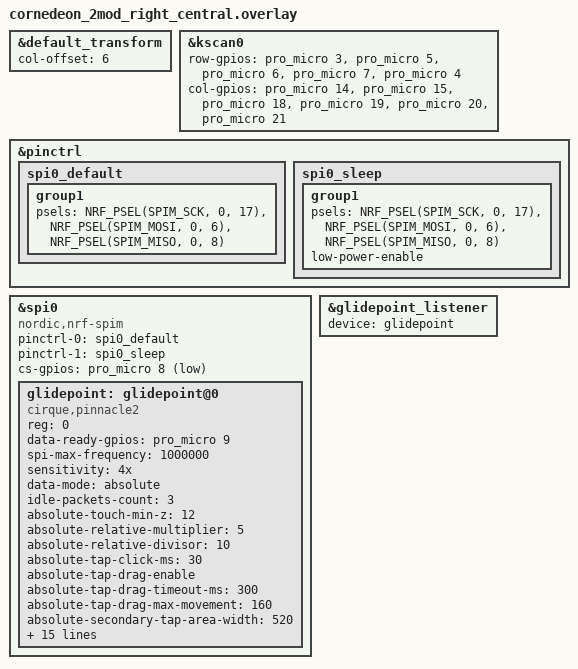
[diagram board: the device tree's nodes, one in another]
#include "cornedeon_2mod.dtsi"

&default_transform {
    col-offset = <6>;
};

&kscan0 {
    row-gpios
        = <&pro_micro 3 (GPIO_ACTIVE_HIGH | GPIO_PULL_DOWN)>
        , <&pro_micro 5 (GPIO_ACTIVE_HIGH | GPIO_PULL_DOWN)>
        , <&pro_micro 6 (GPIO_ACTIVE_HIGH | GPIO_PULL_DOWN)>
        , <&pro_micro 7 (GPIO_ACTIVE_HIGH | GPIO_PULL_DOWN)>
        , <&pro_micro 4 (GPIO_ACTIVE_HIGH | GPIO_PULL_DOWN)>
        ;

    col-gpios
        = <&pro_micro 14 GPIO_ACTIVE_HIGH>
        , <&pro_micro 15 GPIO_ACTIVE_HIGH>
        , <&pro_micro 18 GPIO_ACTIVE_HIGH>
        , <&pro_micro 19 GPIO_ACTIVE_HIGH>
        , <&pro_micro 20 GPIO_ACTIVE_HIGH>
        , <&pro_micro 21 GPIO_ACTIVE_HIGH>
        ;
};

&pinctrl {
    spi0_default: spi0_default {
        group1 {
            psels = <NRF_PSEL(SPIM_SCK, 0, 17)>,  // D2
                    <NRF_PSEL(SPIM_MOSI, 0, 6)>, // D1
                    <NRF_PSEL(SPIM_MISO, 0, 8)>; // D0
        };
    };

    spi0_sleep: spi0_sleep {
        group1 {
            psels = <NRF_PSEL(SPIM_SCK, 0, 17)>,
                    <NRF_PSEL(SPIM_MOSI, 0, 6)>,
                    <NRF_PSEL(SPIM_MISO, 0, 8)>;
            low-power-enable;
        };
    };
};

&spi0 {
    status = "okay";
    compatible = "nordic,nrf-spim";
    pinctrl-0 = <&spi0_default>;
    pinctrl-1 = <&spi0_sleep>;
    pinctrl-names = "default", "sleep";
    
    cs-gpios = <&pro_micro 8 GPIO_ACTIVE_LOW>; 

    glidepoint: glidepoint@0 {
        compatible = "cirque,pinnacle2";
        reg = <0>;
        data-ready-gpios = <&pro_micro 9 (GPIO_ACTIVE_HIGH | GPIO_PULL_DOWN)>;
        spi-max-frequency = <1000000>; /* 1 MHz */
      	sensitivity = "4x";
		data-mode = "absolute";
		idle-packets-count = <3>;
		absolute-touch-min-z = <12>;
		absolute-relative-multiplier = <5>;
		absolute-relative-divisor = <10>;
		absolute-tap-click-ms = <30>;
		absolute-tap-drag-enable;
		absolute-tap-drag-timeout-ms = <300>;
		absolute-tap-drag-max-movement = <160>;
		absolute-secondary-tap-area-width = <520>;
		absolute-secondary-tap-area-height = <420>;
		absolute-aux-tap-area-width = <0>;
		absolute-aux-tap-area-height = <0>;
		absolute-edge-motion-enable;
		absolute-edge-motion-zone = <80>;
		absolute-edge-motion-speed = <4>;
		absolute-edge-motion-interval-ms = <10>;
		absolute-edge-motion-start-ms = <120>;
		absolute-right-edge-scroll-enable;
		absolute-scroll-zone = <240>;
		absolute-scroll-divisor = <50>;
		startup-delay-ms = <1500>;
		primary-tap-enable;
		glide-extend-enable;
		invert-y;
    };
};

&glidepoint_listener {
    status = "okay";
    device = <&glidepoint>;
};

